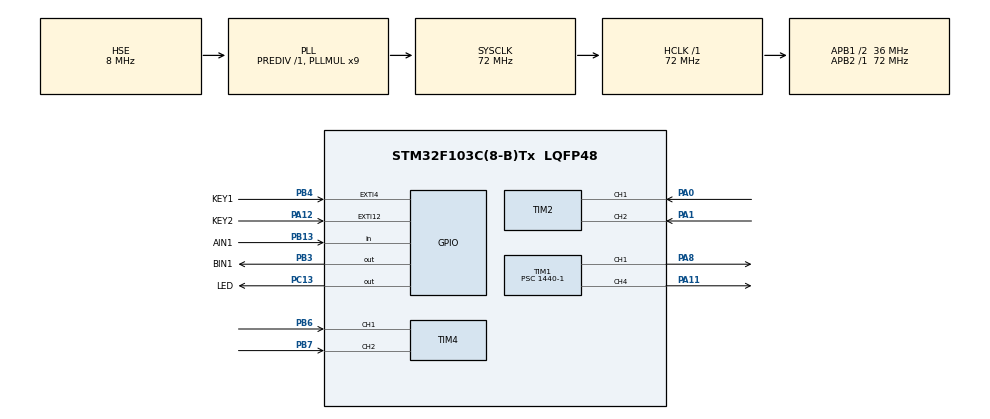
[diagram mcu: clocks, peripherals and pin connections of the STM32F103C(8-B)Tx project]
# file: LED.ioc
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Mcu.Family=STM32F1
Mcu.Name=STM32F103C(8-B)Tx
Mcu.Package=LQFP48
NVIC.EXTI15_10_IRQn=true\:0\:0\:false\:false\:true\:true\:true\:true
NVIC.EXTI4_IRQn=true\:0\:0\:false\:false\:true\:true\:true\:true
NVIC.PriorityGroup=NVIC_PRIORITYGROUP_4
NVIC.TIM2_IRQn=true\:0\:0\:false\:false\:true\:true\:true\:true
NVIC.TIM4_IRQn=true\:0\:0\:false\:false\:true\:true\:true\:true
PA0-WKUP.GPIO_PuPd=GPIO_PULLUP
PA0-WKUP.Signal=S_TIM2_CH1_ETR
PA1.GPIO_PuPd=GPIO_PULLUP
PA1.Signal=S_TIM2_CH2
PA11.Signal=S_TIM1_CH4
PA12.GPIO_Label=KEY2
PA12.GPIO_PuPd=GPIO_PULLUP
PA12.Signal=GPXTI12
PA13.Mode=Serial_Wire
PA13.Signal=SYS_JTMS-SWDIO
PA14.Mode=Serial_Wire
PA14.Signal=SYS_JTCK-SWCLK
PA8.Signal=S_TIM1_CH1
PB13.GPIO_Label=AIN1
PB13.Signal=GPIO_Input
PB3.GPIO_Label=BIN1
PB3.Signal=GPIO_Output
PB4.GPIO_Label=KEY1
PB4.GPIO_PuPd=GPIO_PULLDOWN
PB4.Signal=GPXTI4
PB6.GPIO_PuPd=GPIO_PULLUP
PB6.Signal=S_TIM4_CH1
PB7.GPIO_PuPd=GPIO_PULLUP
PB7.Signal=S_TIM4_CH2
PC13-TAMPER-RTC.GPIO_Label=LED
PC13-TAMPER-RTC.Signal=GPIO_Output
PC14-OSC32_IN.Mode=LSE-External-Clock-Source
PC14-OSC32_IN.Signal=RCC_OSC32_IN
PC15-OSC32_OUT.Mode=LSE-External-Clock-Source
PC15-OSC32_OUT.Signal=RCC_OSC32_OUT
PD0-OSC_IN.Mode=HSE-External-Oscillator
PD0-OSC_IN.Signal=RCC_OSC_IN
PD1-OSC_OUT.Mode=HSE-External-Oscillator
PD1-OSC_OUT.Signal=RCC_OSC_OUT
ProjectManager.HeapSize=0x200
ProjectManager.StackSize=0x400
ProjectManager.TargetToolchain=MDK-ARM V5.32
RCC.AHBFreq_Value=72000000
RCC.APB1CLKDivider=RCC_HCLK_DIV2
RCC.APB1Freq_Value=36000000
RCC.APB1TimFreq_Value=72000000
RCC.APB2Freq_Value=72000000
RCC.APB2TimFreq_Value=72000000
RCC.HCLKFreq_Value=72000000
RCC.PLLMUL=RCC_PLL_MUL9
RCC.PLLSourceVirtual=RCC_PLLSOURCE_HSE
RCC.SYSCLKFreq_VALUE=72000000
RCC.SYSCLKSource=RCC_SYSCLKSOURCE_PLLCLK
RCC.USBFreq_Value=72000000
SH.S_TIM1_CH1.0=TIM1_CH1,PWM Generation1 CH1
SH.S_TIM1_CH4.0=TIM1_CH4,PWM Generation4 CH4
SH.S_TIM2_CH1_ETR.0=TIM2_CH1,Encoder_Interface
SH.S_TIM2_CH2.0=TIM2_CH2,Encoder_Interface
SH.S_TIM4_CH1.0=TIM4_CH1,Encoder_Interface
SH.S_TIM4_CH2.0=TIM4_CH2,Encoder_Interface
TIM1.Channel-PWM\ Generation1\ CH1=TIM_CHANNEL_1
TIM1.Channel-PWM\ Generation4\ CH4=TIM_CHANNEL_4
TIM1.Period=100-1
TIM1.Prescaler=1440-1
TIM1.Pulse-PWM\ Generation1\ CH1=50
TIM1.Pulse-PWM\ Generation4\ CH4=50
TIM2.EncoderMode=TIM_ENCODERMODE_TI12
TIM2.IC1Filter=6
TIM2.IC2Filter=6
TIM4.IC1Filter=6
TIM4.IC2Filter=6
board=custom

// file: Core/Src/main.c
/* USER CODE BEGIN Header */
/**
  ******************************************************************************
  * @file           : main.c
  * @brief          : Main program body
  ******************************************************************************
  * @attention
  *
  * Copyright (c) 2025 STMicroelectronics.
  * All rights reserved.
  *
  * This software is licensed under terms that can be found in the LICENSE file
  * in the root directory of this software component.
  * If no LICENSE file comes with this software, it is provided AS-IS.
  *
  ******************************************************************************
  */
/* USER CODE END Header */
#include "main.h"
#include "tim.h"
#include "gpio.h"

/* USER CODE BEGIN Includes */
#include "stdio.h"
#include "motor.h"
/* USER CODE END Includes */

/* USER CODE BEGIN PV */
short Encoder1Count = 0;//编码器计数器值
short Encoder2Count = 0;

/* USER CODE END PV */

void SystemClock_Config(void);

int main(void)
{

  /* MCU Configuration--------------------------------------------------------*/

  /* Reset of all peripherals, Initializes the Flash interface and the Systick. */
  HAL_Init();

  /* Configure the system clock */
  SystemClock_Config();

  /* Initialize all configured peripherals */
  MX_GPIO_Init();
  MX_TIM1_Init();
  MX_TIM2_Init();
  MX_TIM4_Init();
  /* USER CODE BEGIN 2 */
  HAL_TIM_PWM_Start(&htim1,TIM_CHANNEL_1);//开启定时器1 通道1 PWM输出
  HAL_TIM_PWM_Start(&htim1,TIM_CHANNEL_4);//开启定时器1 通道4 PWM输出
  HAL_TIM_Encoder_Start(&htim2,TIM_CHANNEL_ALL);//开启定时器2
  HAL_TIM_Encoder_Start(&htim4,TIM_CHANNEL_ALL);//开启定时器4
  HAL_TIM_Base_Start_IT(&htim2);				//开启定时器2 中断
  HAL_TIM_Base_Start_IT(&htim4);                //开启定时器4 中断

  /* USER CODE END 2 */

  /* Infinite loop */
  /* USER CODE BEGIN WHILE */
  while (1)
  {
//	__HAL_TIM_SET_COMPARE(&htim1, TIM_CHANNEL_1, 40);
	Motor_Set(30,30);

	HAL_Delay(1000);

    /* USER CODE END WHILE */

  }
}

void SystemClock_Config(void)
{
  RCC_OscInitTypeDef RCC_OscInitStruct = {0};
  RCC_ClkInitTypeDef RCC_ClkInitStruct = {0};

  /** Initializes the RCC Oscillators according to the specified parameters
  * in the RCC_OscInitTypeDef structure.
  */
  RCC_OscInitStruct.OscillatorType = RCC_OSCILLATORTYPE_HSE;
  RCC_OscInitStruct.HSEState = RCC_HSE_ON;
  RCC_OscInitStruct.HSEPredivValue = RCC_HSE_PREDIV_DIV1;
  RCC_OscInitStruct.HSIState = RCC_HSI_ON;
  RCC_OscInitStruct.PLL.PLLState = RCC_PLL_ON;
  RCC_OscInitStruct.PLL.PLLSource = RCC_PLLSOURCE_HSE;
  RCC_OscInitStruct.PLL.PLLMUL = RCC_PLL_MUL9;
  if (HAL_RCC_OscConfig(&RCC_OscInitStruct) != HAL_OK)
  {
    Error_Handler();
  }

  /** Initializes the CPU, AHB and APB buses clocks
  */
  RCC_ClkInitStruct.ClockType = RCC_CLOCKTYPE_HCLK|RCC_CLOCKTYPE_SYSCLK
                              |RCC_CLOCKTYPE_PCLK1|RCC_CLOCKTYPE_PCLK2;
  RCC_ClkInitStruct.SYSCLKSource = RCC_SYSCLKSOURCE_PLLCLK;
  RCC_ClkInitStruct.AHBCLKDivider = RCC_SYSCLK_DIV1;
  RCC_ClkInitStruct.APB1CLKDivider = RCC_HCLK_DIV2;
  RCC_ClkInitStruct.APB2CLKDivider = RCC_HCLK_DIV1;

  if (HAL_RCC_ClockConfig(&RCC_ClkInitStruct, FLASH_LATENCY_2) != HAL_OK)
  {
    Error_Handler();
  }
}

void Error_Handler(void)
{
  __disable_irq();
  while (1)
  {
  }
}
